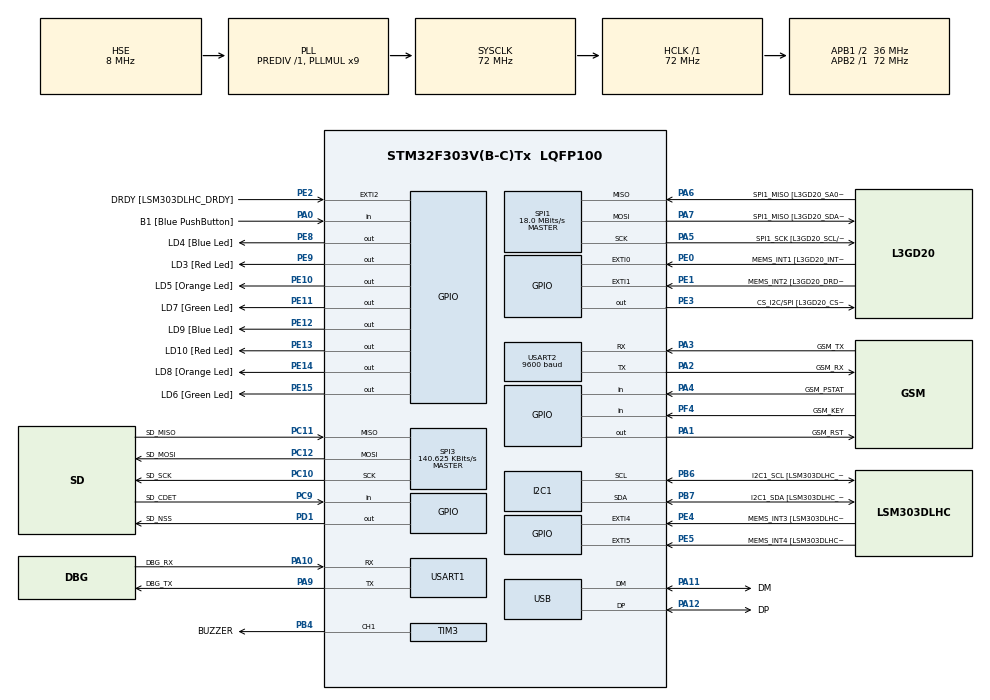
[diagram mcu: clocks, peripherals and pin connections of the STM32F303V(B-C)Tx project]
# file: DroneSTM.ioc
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FREERTOS.HEAP_NUMBER=4
FREERTOS.Tasks01=defaultTask,0,128,StartDefaultTask,Default
FREERTOS.configTOTAL_HEAP_SIZE=8192
I2C1.Timing=0x10808DD3
I2C1.Timing-I2C=0x2000090E
Mcu.Family=STM32F3
Mcu.Name=STM32F303V(B-C)Tx
Mcu.Package=LQFP100
NVIC.PriorityGroup=NVIC_PRIORITYGROUP_4
NVIC.TIM1_UP_TIM16_IRQn=true\:0\:0\:false\:false\:true\:false
NVIC.TimeBase=TIM1_UP_TIM16_IRQn
NVIC.TimeBaseIP=TIM1
NVIC.USB_LP_CAN_RX0_IRQn=true\:5\:0\:false\:false\:true\:true
PA0.GPIO_Label=B1 [Blue PushButton]
PA0.Signal=GPIO_Input
PA1.GPIO_Label=GSM_RST
PA1.GPIO_ModeDefaultOutputPP=GPIO_MODE_OUTPUT_OD
PA1.PinState=GPIO_PIN_SET
PA1.Signal=GPIO_Output
PA10.GPIO_Label=DBG_RX
PA10.Mode=Asynchronous
PA10.Signal=USART1_RX
PA11.GPIO_Label=DM
PA11.Mode=Device
PA11.Signal=USB_DM
PA12.GPIO_Label=DP
PA12.Mode=Device
PA12.Signal=USB_DP
PA13.GPIO_Label=SWDIO
PA13.Mode=Serial_Wire
PA13.Signal=SYS_JTMS-SWDIO
PA14.GPIO_Label=SWCLK
PA14.Mode=Serial_Wire
PA14.Signal=SYS_JTCK-SWCLK
PA2.GPIO_Label=GSM_RX
PA2.Mode=Asynchronous
PA2.Signal=USART2_TX
PA3.GPIO_Label=GSM_TX
PA3.Mode=Asynchronous
PA3.Signal=USART2_RX
PA4.GPIO_Label=GSM_PSTAT
PA4.Signal=GPIO_Input
PA5.GPIO_Label=SPI1_SCK [L3GD20_SCL/SPC]
PA5.Mode=Full_Duplex_Master
PA5.Signal=SPI1_SCK
PA6.GPIO_Label=SPI1_MISO [L3GD20_SA0/SDO]
PA6.Mode=Full_Duplex_Master
PA6.Signal=SPI1_MISO
PA7.GPIO_Label=SPI1_MISO [L3GD20_SDA/SDI/SDO]
PA7.Mode=Full_Duplex_Master
PA7.Signal=SPI1_MOSI
PA9.GPIO_Label=DBG_TX
PA9.Mode=Asynchronous
PA9.Signal=USART1_TX
PB3.GPIO_Label=SWO
PB3.Signal=SYS_JTDO-TRACESWO
PB4.GPIO_Label=BUZZER
PB4.Signal=S_TIM3_CH1
PB6.GPIO_Label=I2C1_SCL [LSM303DLHC_SCL]
PB6.Mode=I2C
PB6.Signal=I2C1_SCL
PB7.GPIO_Label=I2C1_SDA [LSM303DLHC_SDA]
PB7.Mode=I2C
PB7.Signal=I2C1_SDA
PC10.GPIO_Label=SD_SCK
PC10.Mode=Full_Duplex_Master
PC10.Signal=SPI3_SCK
PC11.GPIO_Label=SD_MISO
PC11.GPIO_PuPd=GPIO_PULLUP
PC11.Mode=Full_Duplex_Master
PC11.Signal=SPI3_MISO
PC12.GPIO_Label=SD_MOSI
PC12.Mode=Full_Duplex_Master
PC12.Signal=SPI3_MOSI
PC14-OSC32_IN.Mode=LSE-External-Oscillator
PC14-OSC32_IN.Signal=RCC_OSC32_IN
PC15-OSC32_OUT.GPIO_Label=OSC32_OUT
PC15-OSC32_OUT.Mode=LSE-External-Oscillator
PC15-OSC32_OUT.Signal=RCC_OSC32_OUT
PC9.GPIO_Label=SD_CDET
PC9.GPIO_PuPd=GPIO_PULLUP
PC9.Signal=GPIO_Input
PD1.GPIO_Label=SD_NSS
PD1.Signal=GPIO_Output
PD3.Signal=USART2_CTS
PE0.GPIO_Label=MEMS_INT1 [L3GD20_INT1]
PE0.GPIO_ModeDefaultEXTI=GPIO_MODE_EVT_RISING
PE0.Signal=GPXTI0
PE1.GPIO_Label=MEMS_INT2 [L3GD20_DRDY/INT2]
PE1.GPIO_ModeDefaultEXTI=GPIO_MODE_EVT_RISING
PE1.Signal=GPXTI1
PE10.GPIO_Label=LD5 [Orange Led]
PE10.Signal=GPIO_Output
PE11.GPIO_Label=LD7 [Green Led]
PE11.Signal=GPIO_Output
PE12.GPIO_Label=LD9 [Blue Led]
PE12.Signal=GPIO_Output
PE13.GPIO_Label=LD10 [Red Led]
PE13.Signal=GPIO_Output
PE14.GPIO_Label=LD8 [Orange Led]
PE14.Signal=GPIO_Output
PE15.GPIO_Label=LD6 [Green Led]
PE15.Signal=GPIO_Output
PE2.GPIO_Label=DRDY [LSM303DLHC_DRDY]
PE2.GPIO_ModeDefaultEXTI=GPIO_MODE_EVT_RISING
PE2.Signal=GPXTI2
PE3.GPIO_Label=CS_I2C/SPI [L3GD20_CS_I2C/SPI]
PE3.Signal=GPIO_Output
PE4.GPIO_Label=MEMS_INT3 [LSM303DLHC_INT1]
PE4.GPIO_ModeDefaultEXTI=GPIO_MODE_EVT_RISING
PE4.Signal=GPXTI4
PE5.GPIO_Label=MEMS_INT4 [LSM303DLHC_INT2]
PE5.GPIO_ModeDefaultEXTI=GPIO_MODE_EVT_RISING
PE5.Signal=GPXTI5
PE8.GPIO_Label=LD4 [Blue Led]
PE8.Signal=GPIO_Output
PE9.GPIO_Label=LD3 [Red Led]
PE9.Signal=GPIO_Output
PF0-OSC_IN.GPIO_Label=OSC_IN
PF0-OSC_IN.Mode=HSE-External-Oscillator
PF0-OSC_IN.Signal=RCC_OSC_IN
PF1-OSC_OUT.Mode=HSE-External-Oscillator
PF1-OSC_OUT.Signal=RCC_OSC_OUT
PF4.GPIO_Label=GSM_KEY
PF4.GPIO_PuPd=GPIO_NOPULL
PF4.Signal=GPIO_Input
ProjectManager.HeapSize=0x200
ProjectManager.StackSize=0x400
ProjectManager.TargetToolchain=TrueSTUDIO
RCC.AHBFreq_Value=72000000
RCC.APB1CLKDivider=RCC_HCLK_DIV2
RCC.APB1Freq_Value=36000000
RCC.APB1TimFreq_Value=72000000
RCC.APB2Freq_Value=72000000
RCC.APB2TimFreq_Value=72000000
RCC.CortexFreq_Value=72000000
RCC.HCLKFreq_Value=72000000
RCC.HSE_VALUE=8000000
RCC.HSIState=RCC_HSI_ON
RCC.HSI_VALUE=8000000
RCC.I2c1ClockSelection=RCC_I2C1CLKSOURCE_SYSCLK
RCC.PLLMUL=RCC_PLL_MUL9
RCC.PRESCALERUSB=RCC_USBCLKSOURCE_PLL_DIV1_5
RCC.SYSCLKFreq_VALUE=72000000
RCC.SYSCLKSourceVirtual=RCC_SYSCLKSOURCE_PLLCLK
RCC.USBFreq_Value=48000000
SH.S_TIM3_CH1.0=TIM3_CH1,PWM Generation1 CH1
SPI1.BaudRatePrescaler=SPI_BAUDRATEPRESCALER_4
SPI1.BaudRatePrescaler-Full_Duplex_Master=SPI_BAUDRATEPRESCALER_2
SPI1.CalculateBaudRate=18.0 MBits/s
SPI1.CalculateBaudRate-Full_Duplex_Master=24.0 MBits/s
SPI1.Mode=SPI_MODE_MASTER
SPI1.Mode-Full_Duplex_Master=SPI_MODE_MASTER
SPI3.BaudRatePrescaler=SPI_BAUDRATEPRESCALER_256
SPI3.CalculateBaudRate=140.625 KBits/s
SPI3.DataSize=SPI_DATASIZE_8BIT
SPI3.Mode=SPI_MODE_MASTER
USART2.BaudRate=9600
USB_DEVICE.CLASS_NAME_FS=CDC
USB_DEVICE.USBD_HandleTypeDef=hUsbDeviceFS
USB_DEVICE.VirtualMode=Cdc
USB_DEVICE.VirtualModeFS=Cdc_FS
VP_FATFS_VS_Generic.Mode=User_defined
VP_FREERTOS_VS_ENABLE.Mode=Enabled
VP_SYS_VS_tim1.Mode=TIM1
VP_TIM3_VS_ClockSourceINT.Mode=Internal
VP_USB_DEVICE_VS_USB_DEVICE_CDC_FS.Mode=CDC_FS
board=STM32F3DISCOVERY

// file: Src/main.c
/**
  ******************************************************************************
  * File Name          : main.c
  * Description        : Main program body
  ******************************************************************************
  *
  * COPYRIGHT(c) 2016 STMicroelectronics
  *
  * Redistribution and use in source and binary forms, with or without modification,
  * are permitted provided that the following conditions are met:
  *   1. Redistributions of source code must retain the above copyright notice,
  *      this list of conditions and the following disclaimer.
  *   2. Redistributions in binary form must reproduce the above copyright notice,
  *      this list of conditions and the following disclaimer in the documentation
  *      and/or other materials provided with the distribution.
  *   3. Neither the name of STMicroelectronics nor the names of its contributors
  *      may be used to endorse or promote products derived from this software
  *      without specific prior written permission.
  *
  * THIS SOFTWARE IS PROVIDED BY THE COPYRIGHT HOLDERS AND CONTRIBUTORS "AS IS"
  * AND ANY EXPRESS OR IMPLIED WARRANTIES, INCLUDING, BUT NOT LIMITED TO, THE
  * IMPLIED WARRANTIES OF MERCHANTABILITY AND FITNESS FOR A PARTICULAR PURPOSE ARE
  * DISCLAIMED. IN NO EVENT SHALL THE COPYRIGHT HOLDER OR CONTRIBUTORS BE LIABLE
  * FOR ANY DIRECT, INDIRECT, INCIDENTAL, SPECIAL, EXEMPLARY, OR CONSEQUENTIAL
  * DAMAGES (INCLUDING, BUT NOT LIMITED TO, PROCUREMENT OF SUBSTITUTE GOODS OR
  * SERVICES; LOSS OF USE, DATA, OR PROFITS; OR BUSINESS INTERRUPTION) HOWEVER
  * CAUSED AND ON ANY THEORY OF LIABILITY, WHETHER IN CONTRACT, STRICT LIABILITY,
  * OR TORT (INCLUDING NEGLIGENCE OR OTHERWISE) ARISING IN ANY WAY OUT OF THE USE
  * OF THIS SOFTWARE, EVEN IF ADVISED OF THE POSSIBILITY OF SUCH DAMAGE.
  *
  ******************************************************************************
  */
#include "stm32f3xx_hal.h"
#include "cmsis_os.h"
#include "fatfs.h"
#include "i2c.h"
#include "spi.h"
#include "tim.h"
#include "usart.h"
#include "usb_device.h"
#include "gpio.h"

/* USER CODE BEGIN PV */
/* Private variables ---------------------------------------------------------*/

/* USER CODE END PV */

void SystemClock_Config(void);
void Error_Handler(void);
void MX_FREERTOS_Init(void);

/* USER CODE BEGIN PFP */
/* Private function prototypes -----------------------------------------------*/

/* USER CODE END PFP */

int main(void)
{

  /* MCU Configuration----------------------------------------------------------*/

  /* Reset of all peripherals, Initializes the Flash interface and the Systick. */
  HAL_Init();

  /* Configure the system clock */
  SystemClock_Config();

  /* Initialize all configured peripherals */
  MX_GPIO_Init();
  MX_I2C1_Init();
  MX_SPI1_Init();
  MX_SPI3_Init();
  MX_USART2_UART_Init();
  MX_TIM3_Init();
  MX_USART1_UART_Init();

  /* Call init function for freertos objects (in freertos.c) */
  MX_FREERTOS_Init();

  /* Start scheduler */
  osKernelStart();

  /* We should never get here as control is now taken by the scheduler */

  /* Infinite loop */
  while (1)
  {

  }

}

/** System Clock Configuration
*/
void SystemClock_Config(void)
{

  RCC_OscInitTypeDef RCC_OscInitStruct;
  RCC_ClkInitTypeDef RCC_ClkInitStruct;
  RCC_PeriphCLKInitTypeDef PeriphClkInit;

  RCC_OscInitStruct.OscillatorType = RCC_OSCILLATORTYPE_HSE;
  RCC_OscInitStruct.HSEState = RCC_HSE_ON;
  RCC_OscInitStruct.HSEPredivValue = RCC_HSE_PREDIV_DIV1;
  RCC_OscInitStruct.PLL.PLLState = RCC_PLL_ON;
  RCC_OscInitStruct.PLL.PLLSource = RCC_PLLSOURCE_HSE;
  RCC_OscInitStruct.PLL.PLLMUL = RCC_PLL_MUL9;
  if (HAL_RCC_OscConfig(&RCC_OscInitStruct) != HAL_OK)
  {
    Error_Handler();
  }

  RCC_ClkInitStruct.ClockType = RCC_CLOCKTYPE_HCLK|RCC_CLOCKTYPE_SYSCLK
                              |RCC_CLOCKTYPE_PCLK1|RCC_CLOCKTYPE_PCLK2;
  RCC_ClkInitStruct.SYSCLKSource = RCC_SYSCLKSOURCE_PLLCLK;
  RCC_ClkInitStruct.AHBCLKDivider = RCC_SYSCLK_DIV1;
  RCC_ClkInitStruct.APB1CLKDivider = RCC_HCLK_DIV2;
  RCC_ClkInitStruct.APB2CLKDivider = RCC_HCLK_DIV1;
  if (HAL_RCC_ClockConfig(&RCC_ClkInitStruct, FLASH_LATENCY_2) != HAL_OK)
  {
    Error_Handler();
  }

  PeriphClkInit.PeriphClockSelection = RCC_PERIPHCLK_USB|RCC_PERIPHCLK_USART1
                              |RCC_PERIPHCLK_USART2|RCC_PERIPHCLK_I2C1;
  PeriphClkInit.Usart1ClockSelection = RCC_USART1CLKSOURCE_PCLK2;
  PeriphClkInit.Usart2ClockSelection = RCC_USART2CLKSOURCE_PCLK1;
  PeriphClkInit.I2c1ClockSelection = RCC_I2C1CLKSOURCE_SYSCLK;
  PeriphClkInit.USBClockSelection = RCC_USBCLKSOURCE_PLL_DIV1_5;
  if (HAL_RCCEx_PeriphCLKConfig(&PeriphClkInit) != HAL_OK)
  {
    Error_Handler();
  }

  HAL_SYSTICK_Config(HAL_RCC_GetHCLKFreq()/1000);

  HAL_SYSTICK_CLKSourceConfig(SYSTICK_CLKSOURCE_HCLK);

  /* SysTick_IRQn interrupt configuration */
  HAL_NVIC_SetPriority(SysTick_IRQn, 15, 0);
}

void HAL_TIM_PeriodElapsedCallback(TIM_HandleTypeDef *htim)
{
  if (htim->Instance == TIM1) {
    HAL_IncTick();
  }
}

void Error_Handler(void)
{
  while(1)
  {
  }
}

/************************ (C) COPYRIGHT STMicroelectronics *****END OF FILE****/

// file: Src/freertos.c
/**
  ******************************************************************************
  * File Name          : freertos.c
  * Description        : Code for freertos applications
  ******************************************************************************
  *
  * COPYRIGHT(c) 2016 STMicroelectronics
  *
  * Redistribution and use in source and binary forms, with or without modification,
  * are permitted provided that the following conditions are met:
  *   1. Redistributions of source code must retain the above copyright notice,
  *      this list of conditions and the following disclaimer.
  *   2. Redistributions in binary form must reproduce the above copyright notice,
  *      this list of conditions and the following disclaimer in the documentation
  *      and/or other materials provided with the distribution.
  *   3. Neither the name of STMicroelectronics nor the names of its contributors
  *      may be used to endorse or promote products derived from this software
  *      without specific prior written permission.
  *
  * THIS SOFTWARE IS PROVIDED BY THE COPYRIGHT HOLDERS AND CONTRIBUTORS "AS IS"
  * AND ANY EXPRESS OR IMPLIED WARRANTIES, INCLUDING, BUT NOT LIMITED TO, THE
  * IMPLIED WARRANTIES OF MERCHANTABILITY AND FITNESS FOR A PARTICULAR PURPOSE ARE
  * DISCLAIMED. IN NO EVENT SHALL THE COPYRIGHT HOLDER OR CONTRIBUTORS BE LIABLE
  * FOR ANY DIRECT, INDIRECT, INCIDENTAL, SPECIAL, EXEMPLARY, OR CONSEQUENTIAL
  * DAMAGES (INCLUDING, BUT NOT LIMITED TO, PROCUREMENT OF SUBSTITUTE GOODS OR
  * SERVICES; LOSS OF USE, DATA, OR PROFITS; OR BUSINESS INTERRUPTION) HOWEVER
  * CAUSED AND ON ANY THEORY OF LIABILITY, WHETHER IN CONTRACT, STRICT LIABILITY,
  * OR TORT (INCLUDING NEGLIGENCE OR OTHERWISE) ARISING IN ANY WAY OUT OF THE USE
  * OF THIS SOFTWARE, EVEN IF ADVISED OF THE POSSIBILITY OF SUCH DAMAGE.
  *
  ******************************************************************************
  */

#include "FreeRTOS.h"
#include "task.h"
#include "cmsis_os.h"

/* USER CODE BEGIN Includes */
#include "gpio.h"
#include "usbd_cdc_if.h"
#include "config.h"
#include "App/SIM808.hh"
/* USER CODE END Includes */

osThreadId defaultTaskHandle;

/* USER CODE BEGIN Variables */

osThreadId secondTaskHandle;
extern USBD_HandleTypeDef hUsbDeviceFS;

/* USER CODE END Variables */

void StartDefaultTask(void const * argument);

extern void MX_FATFS_Init(void);
extern void MX_USB_DEVICE_Init(void);
void MX_FREERTOS_Init(void); /* (MISRA C 2004 rule 8.1) */

/* USER CODE BEGIN FunctionPrototypes */

void StartSecondTask(void const * argument);

/* USER CODE END FunctionPrototypes */

/* Hook prototypes */

/* Init FreeRTOS */

void MX_FREERTOS_Init(void) {

  /* Create the thread(s) */
  /* definition and creation of defaultTask */
  osThreadDef(defaultTask, StartDefaultTask, osPriorityNormal, 0, 128);
  defaultTaskHandle = osThreadCreate(osThread(defaultTask), NULL);

  /* USER CODE BEGIN RTOS_THREADS */
  /* add threads, ... */
  osThreadDef(secondTask, SIM808_Task, osPriorityNormal, 0, 512);
  secondTaskHandle = osThreadCreate(osThread(secondTask), NULL);
  /* USER CODE END RTOS_THREADS */

}

/* StartDefaultTask function */
void StartDefaultTask(void const * argument)
{
  /* init code for FATFS */
  MX_FATFS_Init();

  /* init code for USB_DEVICE */
  MX_USB_DEVICE_Init();

  /* USER CODE BEGIN StartDefaultTask */
  /* Infinite loop */
  for(;;)
  {
    /* turn off current led and turn on the next one */
    //HAL_GPIO_WritePin(LD3_GPIO_Port, 1 << (8 + phase), GPIO_PIN_RESET);
    //phase++;
    //if (phase == 8) phase = 0;
    //HAL_GPIO_WritePin(LD3_GPIO_Port, 1 << (8 + phase), GPIO_PIN_SET);
    /* toggle led */
    HAL_GPIO_TogglePin(LD3_GPIO_Port, (1 << 12));
    /* delay */
    osDelay(1000);

    //serWriteString("AT\r\n");
  }
  /* USER CODE END StartDefaultTask */
}

/************************ (C) COPYRIGHT STMicroelectronics *****END OF FILE****/
